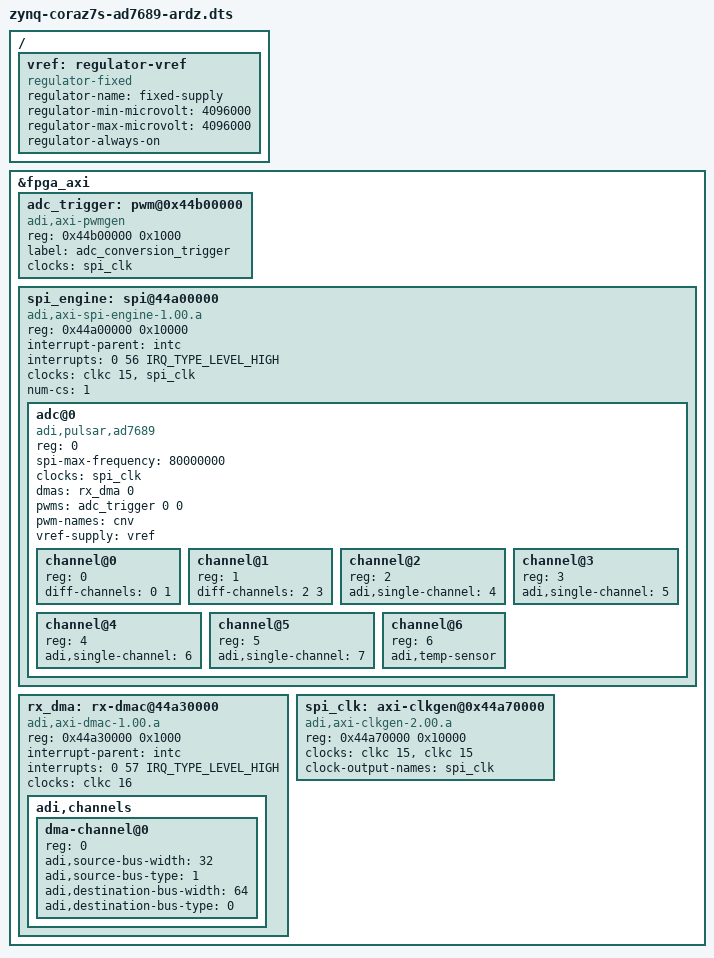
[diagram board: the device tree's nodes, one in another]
// SPDX-License-Identifier: GPL-2.0
/*
 * board_revision: <A>
 *
 * Copyright (C) 2022 Analog Devices Inc.
 */
/dts-v1/;
#include "zynq-coraz7s.dtsi"
#include <dt-bindings/interrupt-controller/irq.h>
#include <dt-bindings/gpio/gpio.h>

/ {
	vref: regulator-vref {
		compatible = "regulator-fixed";
		regulator-name = "fixed-supply";
		regulator-min-microvolt = <4096000>;
		regulator-max-microvolt = <4096000>;
		regulator-always-on;
	};
};

&fpga_axi {

	adc_trigger: pwm@0x44b00000 {
		compatible = "adi,axi-pwmgen";
		reg = <0x44b00000 0x1000>;
		label = "adc_conversion_trigger";
		#pwm-cells = <2>;
		clocks = <&spi_clk>;
	};

	spi_engine: spi@44a00000 {
		compatible = "adi,axi-spi-engine-1.00.a";
		reg = <0x44a00000 0x10000>;
		interrupt-parent = <&intc>;
		interrupts = <0 56 IRQ_TYPE_LEVEL_HIGH>;
		clocks = <&clkc 15 &spi_clk>;
		clock-names = "s_axi_aclk", "spi_clk";
		num-cs = <1>;

		#address-cells = <0x1>;
		#size-cells = <0x0>;

		adc@0 {
			#address-cells = <1>;
			#size-cells = <0>;
			compatible = "adi,pulsar,ad7689";
			reg = <0>;
			spi-max-frequency = <80000000>;
			clocks = <&spi_clk>;
			clock-names = "ref_clk";
			dmas = <&rx_dma 0>;
			dma-names = "rx";
			pwms = <&adc_trigger 0 0>;
			pwm-names = "cnv";
			vref-supply = <&vref>;
			channel@0 {
                        	reg = <0>;
                        	diff-channels = <0 1>;
                	};
                	channel@1 {
                        	reg = <1>;
                        	diff-channels = <2 3>;
                	};
                	channel@2 {
                        	reg = <2>;
                        	adi,single-channel = <4>;
                	};
                	channel@3 {
                        	reg = <3>;
                        	adi,single-channel = <5>;
                	};
                	channel@4 {
                        	reg = <4>;
                        	adi,single-channel = <6>;
                	};
                	channel@5 {
                        	reg = <5>;
                        	adi,single-channel = <7>;
                	};
                	channel@6 {
                        	reg = <6>;
                        	adi,temp-sensor;
                	};
		};
	};

	rx_dma: rx-dmac@44a30000 {
		compatible = "adi,axi-dmac-1.00.a";
		reg = <0x44a30000 0x1000>;
		#dma-cells = <1>;
		interrupt-parent = <&intc>;
		interrupts = <0 57 IRQ_TYPE_LEVEL_HIGH>;
		clocks = <&clkc 16>;

		adi,channels {
			#size-cells = <0>;
			#address-cells = <1>;

			dma-channel@0 {
				reg = <0>;
				adi,source-bus-width = <32>;
				adi,source-bus-type = <1>;
				adi,destination-bus-width = <64>;
				adi,destination-bus-type = <0>;
			};
		};
	};

	spi_clk: axi-clkgen@0x44a70000 {
		compatible = "adi,axi-clkgen-2.00.a";
		reg = <0x44a70000 0x10000>;
		#clock-cells = <0>;
		clocks = <&clkc 15>, <&clkc 15>;
		clock-names = "s_axi_aclk", "clkin1";
		clock-output-names = "spi_clk";
	};
};
